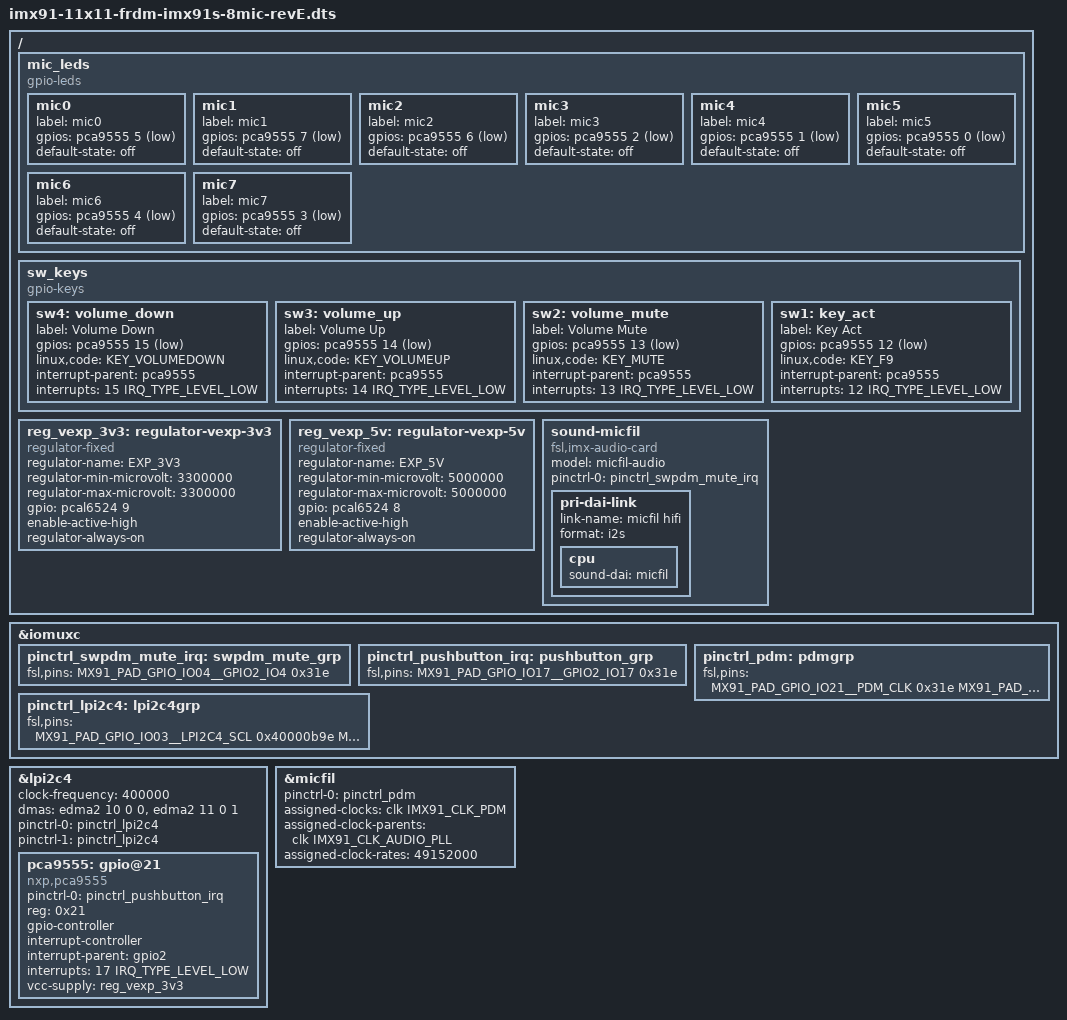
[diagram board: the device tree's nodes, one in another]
// SPDX-License-Identifier: (GPL-2.0+ OR MIT)
/*
 * Copyright 2025 NXP
 */

#include "imx91-11x11-frdm-imx91s.dts"

/ {
	mic_leds {
		compatible = "gpio-leds";
		mic0 {
			label = "mic0";
			gpios = <&pca9555 5 GPIO_ACTIVE_LOW>;
			default-state = "off";
		};
		mic1 {
			label = "mic1";
			gpios = <&pca9555 7 GPIO_ACTIVE_LOW>;
			default-state = "off";
		};
		mic2 {
			label = "mic2";
			gpios = <&pca9555 6 GPIO_ACTIVE_LOW>;
			default-state = "off";
		};
		mic3 {
			label = "mic3";
			gpios = <&pca9555 2 GPIO_ACTIVE_LOW>;
			default-state = "off";
		};
		mic4 {
			label = "mic4";
			gpios = <&pca9555 1 GPIO_ACTIVE_LOW>;
			default-state = "off";
		};
		mic5 {
			label = "mic5";
			gpios = <&pca9555 0 GPIO_ACTIVE_LOW>;
			default-state = "off";
		};
		mic6 {
			label = "mic6";
			gpios = <&pca9555 4 GPIO_ACTIVE_LOW>;
			default-state = "off";
		};
		mic7 {
			label = "mic7";
			gpios = <&pca9555 3 GPIO_ACTIVE_LOW>;
			default-state = "off";
		};
	};

	sw_keys {
		compatible = "gpio-keys";

		sw4: volume_down {
			label = "Volume Down";
			gpios = <&pca9555 15 GPIO_ACTIVE_LOW>;
			linux,code = <KEY_VOLUMEDOWN>;
			interrupt-parent = <&pca9555>;
			interrupts = <15 IRQ_TYPE_LEVEL_LOW>;
		};

		sw3: volume_up {
			label = "Volume Up";
			gpios = <&pca9555 14 GPIO_ACTIVE_LOW>;
			linux,code = <KEY_VOLUMEUP>;
			interrupt-parent = <&pca9555>;
			interrupts = <14 IRQ_TYPE_LEVEL_LOW>;
		};

		sw2: volume_mute {
			label = "Volume Mute";
			gpios = <&pca9555 13 GPIO_ACTIVE_LOW>;
			linux,code = <KEY_MUTE>;
			interrupt-parent = <&pca9555>;
			interrupts = <13 IRQ_TYPE_LEVEL_LOW>;
		};

		sw1: key_act {
			label = "Key Act";
			gpios = <&pca9555 12 GPIO_ACTIVE_LOW>;
			linux,code = <KEY_F9>;
			interrupt-parent = <&pca9555>;
			interrupts = <12 IRQ_TYPE_LEVEL_LOW>;
		};
	};

	reg_vexp_3v3: regulator-vexp-3v3 {
		compatible = "regulator-fixed";
		regulator-name = "EXP_3V3";
		regulator-min-microvolt = <3300000>;
		regulator-max-microvolt = <3300000>;
		gpio = <&pcal6524 9 GPIO_ACTIVE_HIGH>;
		enable-active-high;
		regulator-always-on;
	};

	reg_vexp_5v: regulator-vexp-5v {
		compatible = "regulator-fixed";
		regulator-name = "EXP_5V";
		regulator-min-microvolt = <5000000>;
		regulator-max-microvolt = <5000000>;
		gpio = <&pcal6524 8 GPIO_ACTIVE_HIGH>;
		enable-active-high;
		regulator-always-on;
	};

	sound-micfil {
		compatible = "fsl,imx-audio-card";
		model = "micfil-audio";
		pinctrl-names = "default";
		pinctrl-0 = <&pinctrl_swpdm_mute_irq>;
		pri-dai-link {
			link-name = "micfil hifi";
			format = "i2s";
			cpu {
				sound-dai = <&micfil>;
			};
		};
	};
};

&iomuxc {
	pinctrl_swpdm_mute_irq: swpdm_mute_grp {
		fsl,pins = <
			MX91_PAD_GPIO_IO04__GPIO2_IO4		0x31e
		>;
	};

	pinctrl_pushbutton_irq: pushbutton_grp {
		fsl,pins = <
			MX91_PAD_GPIO_IO17__GPIO2_IO17		0x31e
		>;
	};

	pinctrl_pdm: pdmgrp {
		fsl,pins = <
			MX91_PAD_GPIO_IO21__PDM_CLK		0x31e
			MX91_PAD_GPIO_IO20__PDM_BIT_STREAM0	0x31e
			MX91_PAD_GPIO_IO26__PDM_BIT_STREAM1	0x31e
			MX91_PAD_GPIO_IO16__PDM_BIT_STREAM2	0x31e
			MX91_PAD_GPIO_IO19__PDM_BIT_STREAM3	0x31e
		>;
	};

	pinctrl_lpi2c4: lpi2c4grp {
		fsl,pins = <
			MX91_PAD_GPIO_IO03__LPI2C4_SCL		0x40000b9e
			MX91_PAD_GPIO_IO02__LPI2C4_SDA		0x40000b9e
		>;
	};
};

&lpi2c4 {
	clock-frequency = <400000>;
	dmas = <&edma2 10 0 0>, <&edma2 11 0 1>;
	dma-names = "tx","rx";
	pinctrl-names = "default", "sleep";
	pinctrl-0 = <&pinctrl_lpi2c4>;
	pinctrl-1 = <&pinctrl_lpi2c4>;
	status = "okay";

	pca9555: gpio@21 {
		compatible = "nxp,pca9555";
		pinctrl-names = "default";
		pinctrl-0 = <&pinctrl_pushbutton_irq>;
		reg = <0x21>;
		gpio-controller;
		#gpio-cells = <2>;
		interrupt-controller;
		#interrupt-cells = <2>;
		interrupt-parent = <&gpio2>;
		interrupts = <17 IRQ_TYPE_LEVEL_LOW>;
		vcc-supply = <&reg_vexp_3v3>;
	};
};

&micfil {
	#sound-dai-cells = <0>;
	pinctrl-names = "default";
	pinctrl-0 = <&pinctrl_pdm>;
	assigned-clocks = <&clk IMX91_CLK_PDM>;
	assigned-clock-parents = <&clk IMX91_CLK_AUDIO_PLL>;
	assigned-clock-rates = <49152000>;
	status = "okay";
};
